# HC32F4A8 register map
File version: 1.0
CPU: CM4 r0p1, little endian, MPU, FPU, 4 interrupt priority bits
Registers are 32-bit, read-write, reset 0x0 unless marked. A register's access mark holds for its fields unless they carry their own. Offsets are from the block's base; [hi:lo] are bit positions; {n}, {i} and the like mark numbered series.

## DMC
Base 0x88000400
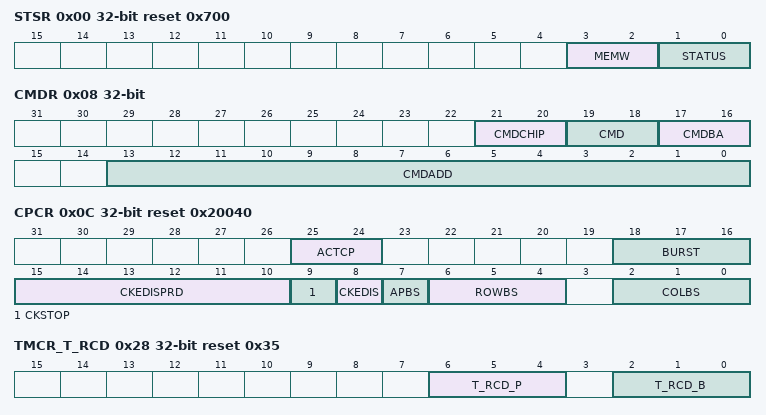
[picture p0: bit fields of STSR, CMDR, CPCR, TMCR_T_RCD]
0x00 STSR ro reset 0x700
  [3:2] MEMW, [1:0] STATUS
0x04 STCR wo
  [2:0] STCTL
0x08 CMDR wo
  [21:20] CMDCHIP, [19:18] CMD, [17:16] CMDBA, [13:0] CMDADD
0x0C CPCR reset 0x20040
  [25:24] ACTCP, [18:16] BURST, [15:10] CKEDISPRD, [9] CKSTOP, [8] CKEDIS, [7] APBS, [6:4] ROWBS, [2:0] COLBS
0x10 RFTR reset 0xA60
  [14:0] REFPRD
0x14 TMCR_T_CASL reset 0x3
  [2:0] T_CASL
0x18 TMCR_T_DQSS reset 0x1
  [1:0] T_DQSS
0x1C TMCR_T_MRD reset 0x2
  [6:0] T_MRD
0x20 TMCR_T_RAS reset 0x7
  [3:0] T_RAS
0x24 TMCR_T_RC reset 0xB
  [3:0] T_RC
0x28 TMCR_T_RCD reset 0x35
  [6:4] T_RCD_P, [2:0] T_RCD_B
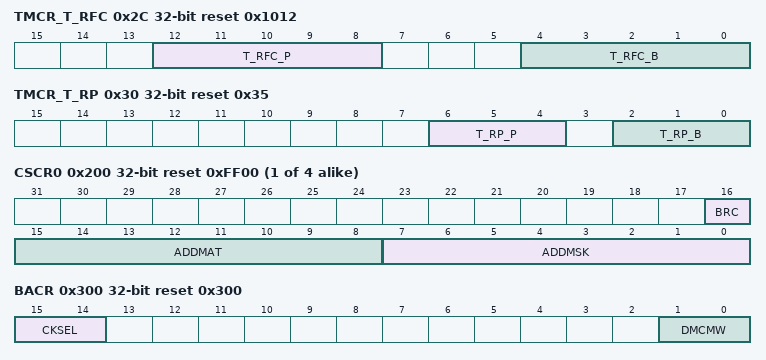
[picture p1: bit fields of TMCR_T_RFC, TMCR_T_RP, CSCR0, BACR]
0x2C TMCR_T_RFC reset 0x1012
  [12:8] T_RFC_P, [4:0] T_RFC_B
0x30 TMCR_T_RP reset 0x35
  [6:4] T_RP_P, [2:0] T_RP_B
0x34 TMCR_T_RRD reset 0x2
  [3:0] T_RRD
0x38 TMCR_T_WR reset 0x3
  [2:0] T_WR
0x3C TMCR_T_WTR reset 0x2
  [2:0] T_WTR
0x40 TMCR_T_XP reset 0x1
  [7:0] T_XP
0x44 TMCR_T_XSR reset 0xA
  [7:0] T_XSR
0x48 TMCR_T_ESR reset 0x14
  [7:0] T_ESR
{0x200+4i} CSCR{i} reset 0xFF00 (i=0..3)
  [16] BRC, [15:8] ADDMAT, [7:0] ADDMSK
0x300 BACR reset 0x300
  [15:14] CKSEL, [1:0] DMCMW

## DVP
Base 0x40055800
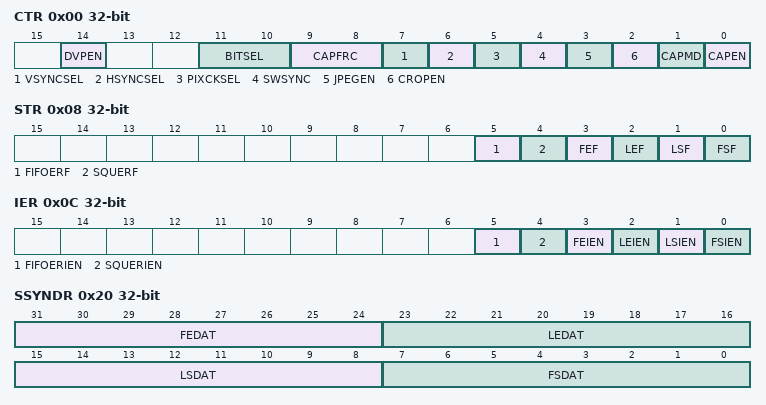
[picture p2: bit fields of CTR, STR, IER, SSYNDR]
0x00 CTR
  [14] DVPEN, [11:10] BITSEL, [9:8] CAPFRC, [7] VSYNCSEL, [6] HSYNCSEL, [5] PIXCKSEL, [4] SWSYNC, [3] JPEGEN, [2] CROPEN, [1] CAPMD, [0] CAPEN
0x04 DTR ro
0x08 STR
  [5] FIFOERF, [4] SQUERF, [3] FEF, [2] LEF, [1] LSF, [0] FSF
0x0C IER
  [5] FIFOERIEN, [4] SQUERIEN, [3] FEIEN, [2] LEIEN, [1] LSIEN, [0] FSIEN
0x10 DMR ro
0x20 SSYNDR
  [31:24] FEDAT, [23:16] LEDAT, [15:8] LSDAT, [7:0] FSDAT
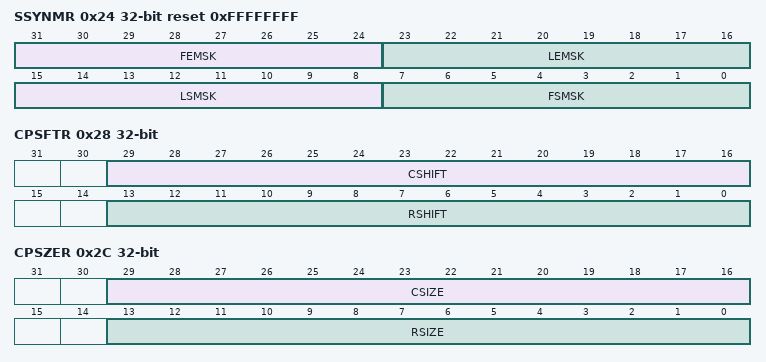
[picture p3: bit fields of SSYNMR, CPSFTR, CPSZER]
0x24 SSYNMR reset 0xFFFFFFFF
  [31:24] FEMSK, [23:16] LEMSK, [15:8] LSMSK, [7:0] FSMSK
0x28 CPSFTR
  [29:16] CSHIFT, [13:0] RSHIFT
0x2C CPSZER
  [29:16] CSIZE, [13:0] RSIZE

## EFM
Base 0x40010400
0x00 FAPRT
  [15:0] FAPRT
0x04 KEY1
0x08 KEY2
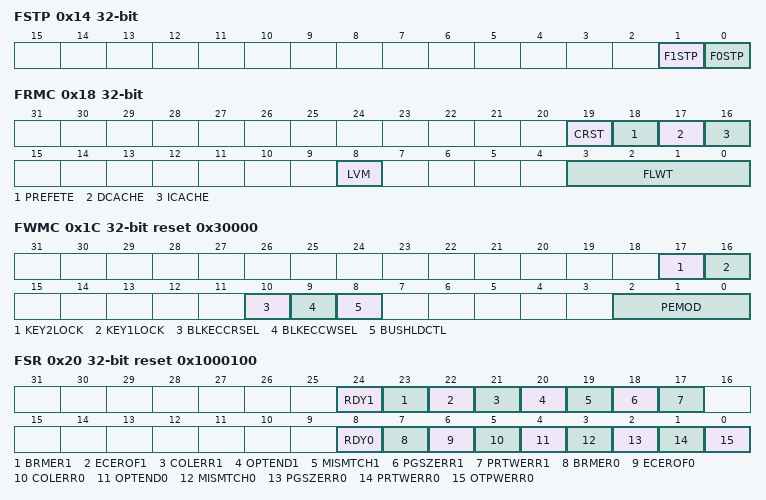
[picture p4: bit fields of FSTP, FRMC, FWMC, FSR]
0x14 FSTP
  [1] F1STP, [0] F0STP
0x18 FRMC
  [19] CRST, [18] PREFETE, [17] DCACHE, [16] ICACHE, [8] LVM, [3:0] FLWT
0x1C FWMC reset 0x30000
  [17] KEY2LOCK, [16] KEY1LOCK, [10] BLKECCRSEL, [9] BLKECCWSEL, [8] BUSHLDCTL, [2:0] PEMOD
0x20 FSR ro reset 0x1000100
  [24] RDY1, [23] BRMER1, [22] ECEROF1, [21] COLERR1, [20] OPTEND1, [19] MISMTCH1, [18] PGSZERR1, [17] PRTWERR1, [8] RDY0, [7] BRMER0, [6] ECEROF0, [5] COLERR0, [4] OPTEND0, [3] MISMTCH0, [2] PGSZERR0, [1] PRTWERR0, [0] OTPWERR0
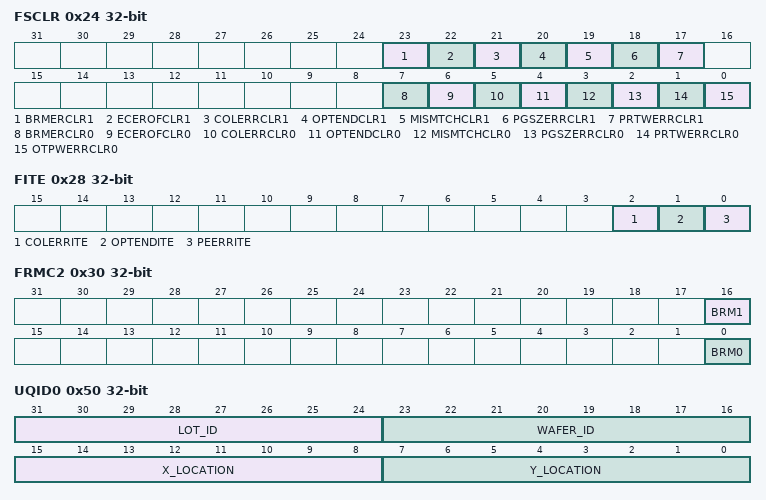
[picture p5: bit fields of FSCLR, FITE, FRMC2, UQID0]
0x24 FSCLR
  [23] BRMERCLR1, [22] ECEROFCLR1, [21] COLERRCLR1, [20] OPTENDCLR1, [19] MISMTCHCLR1, [18] PGSZERRCLR1, [17] PRTWERRCLR1, [7] BRMERCLR0, [6] ECEROFCLR0, [5] COLERRCLR0, [4] OPTENDCLR0, [3] MISMTCHCLR0, [2] PGSZERRCLR0, [1] PRTWERRCLR0, [0] OTPWERRCLR0
0x28 FITE
  [2] COLERRITE, [1] OPTENDITE, [0] PEERRITE
0x2C FSWP ro
  [0] FSWP
0x30 FRMC2
  [16] BRM1, [0] BRM0
0x40 CHIPID ro reset 0x584804A8
0x44 CHIPSEL reset 0x1
  [0] CHIPSEL
0x50 UQID0 ro
  [31:24] LOT_ID, [23:16] WAFER_ID, [15:8] X_LOCATION, [7:0] Y_LOCATION
0x54 UQID1 ro
0x58 UQID2 ro
  [7:0] LOT_ID
0x100 MMF_REMPRT
  [15:0] MMF_REMPRT
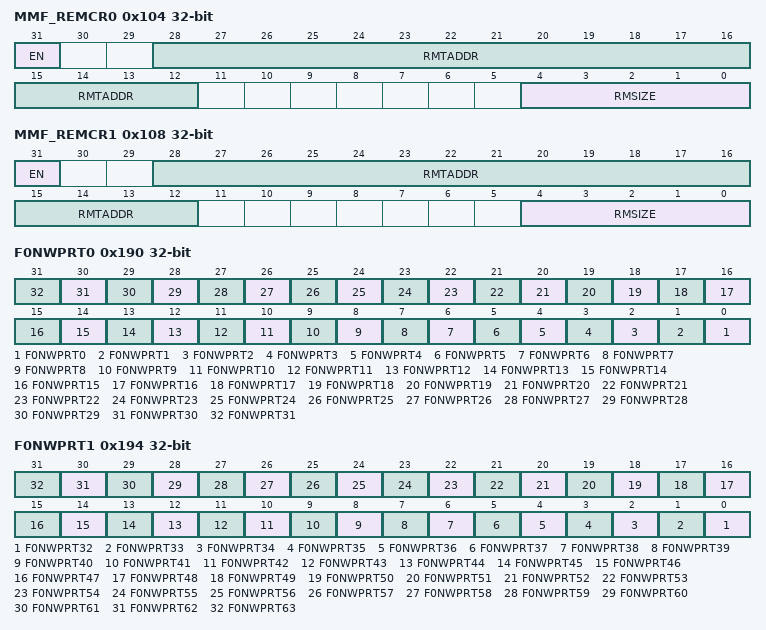
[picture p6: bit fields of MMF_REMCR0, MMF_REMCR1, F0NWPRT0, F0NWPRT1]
0x104 MMF_REMCR0
  [31] EN, [28:12] RMTADDR, [4:0] RMSIZE
0x108 MMF_REMCR1
  [31] EN, [28:12] RMTADDR, [4:0] RMSIZE
0x180 WLOCK
  [7:0] WLOCK
0x190 F0NWPRT0
  [n] F0NWPRT{n} (n=0..31)
0x194 F0NWPRT1
  [n-32] F0NWPRT{n} (n=32..63)
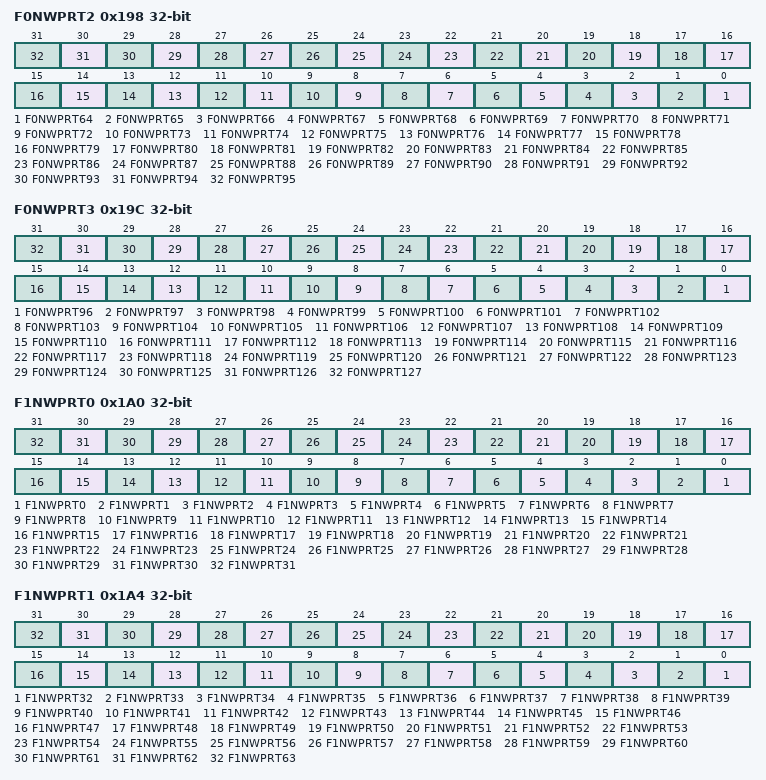
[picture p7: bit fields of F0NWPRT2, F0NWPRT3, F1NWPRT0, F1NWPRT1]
0x198 F0NWPRT2
  [n-64] F0NWPRT{n} (n=64..95)
0x19C F0NWPRT3
  [n-96] F0NWPRT{n} (n=96..127)
0x1A0 F1NWPRT0
  [n] F1NWPRT{n} (n=0..31)
0x1A4 F1NWPRT1
  [n-32] F1NWPRT{n} (n=32..63)
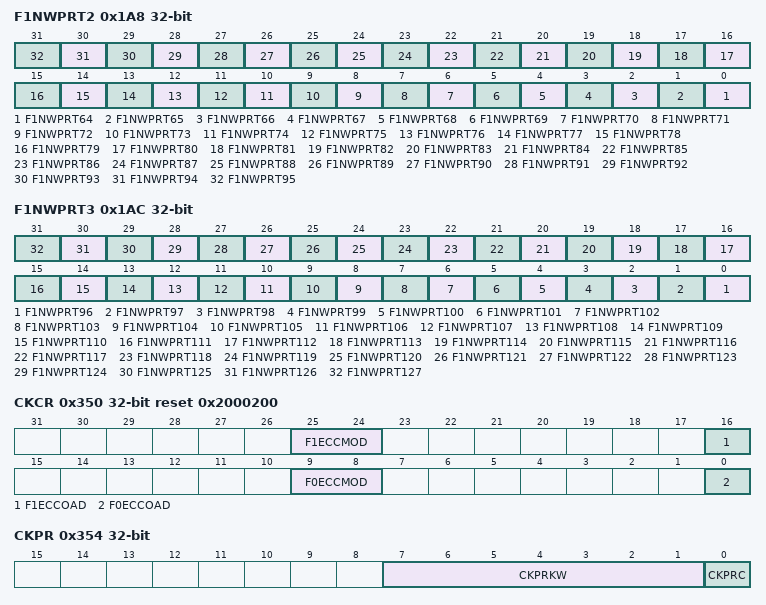
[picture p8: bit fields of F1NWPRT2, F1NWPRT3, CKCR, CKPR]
0x1A8 F1NWPRT2
  [n-64] F1NWPRT{n} (n=64..95)
0x1AC F1NWPRT3
  [n-96] F1NWPRT{n} (n=96..127)
0x350 CKCR reset 0x2000200
  [25:24] F1ECCMOD, [16] F1ECCOAD, [9:8] F0ECCMOD, [0] F0ECCOAD
0x354 CKPR
  [7:1] CKPRKW, [0] CKPRC
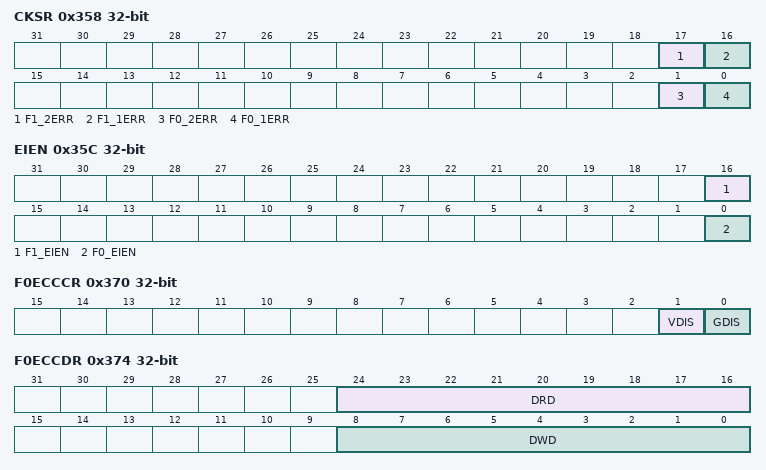
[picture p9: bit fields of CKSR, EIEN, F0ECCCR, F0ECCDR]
0x358 CKSR
  [17] F1_2ERR, [16] F1_1ERR, [1] F0_2ERR, [0] F0_1ERR
0x35C EIEN
  [16] F1_EIEN, [0] F0_EIEN
0x370 F0ECCCR
  [1] VDIS, [0] GDIS
0x374 F0ECCDR
  [24:16] DRD ro, [8:0] DWD
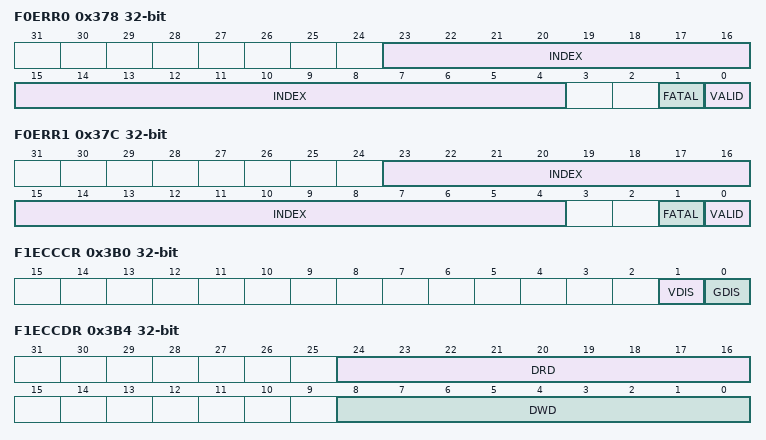
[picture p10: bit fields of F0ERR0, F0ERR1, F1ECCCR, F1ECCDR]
0x378 F0ERR0
  [23:4] INDEX ro, [1] FATAL, [0] VALID
0x37C F0ERR1
  [23:4] INDEX ro, [1] FATAL, [0] VALID
{0x380+4i} F0EIR{i} (i=0..4)
0x3B0 F1ECCCR
  [1] VDIS, [0] GDIS
0x3B4 F1ECCDR
  [24:16] DRD ro, [8:0] DWD
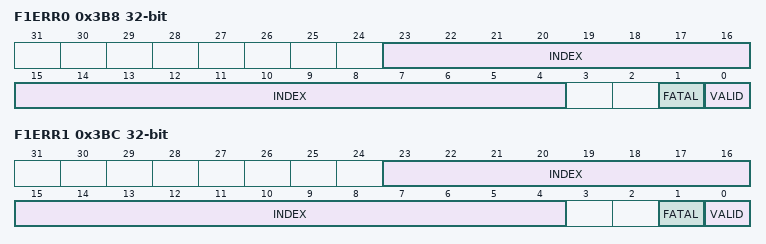
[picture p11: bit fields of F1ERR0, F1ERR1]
0x3B8 F1ERR0
  [23:4] INDEX ro, [1] FATAL, [0] VALID
0x3BC F1ERR1
  [23:4] INDEX ro, [1] FATAL, [0] VALID
{0x3C0+4i} F1EIR{i} (i=0..4)
